# AM13E23219 register map
Vendor: Texas Instruments; File version: 1.0
CPU: CM33 r0p1, little endian, MPU, FPU, VTOR, 4 interrupt priority bits
Registers are 32-bit, read-write, reset 0x0 unless marked. A register's access mark holds for its fields unless they carry their own. Offsets are from the block's base; [hi:lo] are bit positions; lines under a group give offsets from that group; {n}, {i} and the like mark numbered series; 'fields as' and 'values as' point back to an identical list.

## INPUTXBAR — INPUT_XBAR module
Base 0x40468000
{0x0+4i} INPUTSELECT[{i}] (i=0..27) — Input Select Register (GPIO0 to x)
  [7:0] SELECT — Select GPIO for INPUT{#} signal
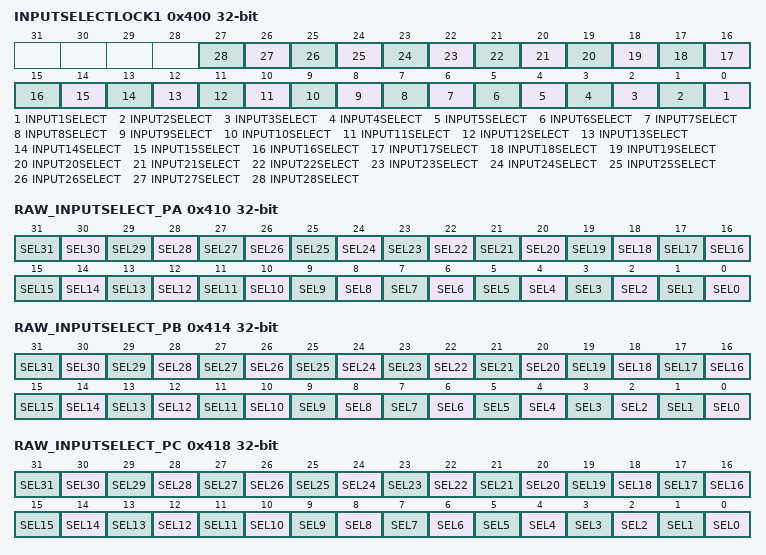
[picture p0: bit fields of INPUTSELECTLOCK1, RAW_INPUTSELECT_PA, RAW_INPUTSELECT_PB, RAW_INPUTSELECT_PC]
0x400 INPUTSELECTLOCK1 — Input Select Lock Register 1
  [n-1] INPUT{n}SELECT (n=1..28) — Lock bit for INPUT{n}SELECT Register
0x404 PINCM group
  {0x0+4j} I_GPIO0_SRC_IN_{j} (j=0..31) — GPIO0 pin {j} functional input signal from external pad to crossbar peripheral
    [30] GFLT — Glitch Filter Enable
      0=DISABLE (No internal glitch filter); 1=ENABLE (Use internal glitch filter)
    [29] SLEW — Reserved Slew Rate Control
      0=DISABLE (No Slew Rate Control); 1=ENABLE (Use Slew Rate Control)
    [28] WCOMP — Wake up compare value
      0=MATCH_ZERO (Match 0 will wake); 1=MATCH_ONE (Match 1 will wake)
    [27] WUEN — Wake up enable
      0=NO_WAKEUP (Wake up not enabled); 1=WAKEUP (Wake up enabled)
    [26] INV — Invert digital input/output relative to peripheral/GPIO
      0=NO_CHNG (Input and output are non-inverted); 1=CHNG (Input and output are inverted)
    [25] HIGHZ1 — High-Z instead of high output
      0=DRV_HIGH (Pin can be driven high); 1=DRV_HIZ (Pin is tri-stated instead of driven high)
    [24] HIGHZ0 — High-Z instead of low output
      0=DRV_LOW (Pin can be driven low); 1=DRV_HIZ (Pin is tri-stated instead of driven low)
    [22:20] DRV — Drive strength options
      0=STRENGTH_0 (Lowest drive strength); {v}=STRENGTH_{v} (Drive strength {v+1}/8) (v=1..6); 7=STRENGTH_7 (Highest drive strength)
    [19] HYSTEN — Hysteresis enable
      0=DIS_HYST (No hysteresis); 1=EN_HYST (Hysteresis on)
    [18] INENA — Input enable
      0=INP_DISABLE (Inputs 0 to connected core); 1=INP_ENABLE (Inputs IO pad value to connected core)
    [17] PIPU — Pull up enable
      0=NO_PULL_UP; 1=PULL_UP
    [16] PIPD — Pull down enable
      0=NO_PULL_DOWN; 1=PULL_DOWN
    [15:14] GSTATE — GPIO Channel State
      0=UNASSIGNED (G-Channel is in Unassigned State); 1=HANDOVER (G-Channel is in Handover State); 2=CONC_NOT_LOCKED (G-Channel is in Connected State and not Locked (That is F field is allowed to change without going back through Unassigned state)); 3=CONC_LOCKED (G-Channel is in Connected State and Locked (That is F field is not allowed to change to a different non-Zero value until both G and P channels go to Unassigned))
    [7:6] PSTATE — Peripheral-Analog Channel State
      0=UNASSIGNED (P-Channel is in Unassigned State); 1=HANDOVER (P-Channel is in Handover State); 2=CONC_NOT_LOCKED (P-Channel is in Connected State and not Locked (That is F field is allowed to change without going back through Unassigned state)); 3=CONC_LOCKED (P-Channel is in Connected State and Locked (That is F field is not allowed to change to a different non-Zero value until both G and P channels go to Unassigned))
  {0x80+4j} I_GPIO1_SRC_IN_{j} (j=0..31) — GPIO1 pin {j} functional input signal from external pad to crossbar peripheral
    fields as PINCM.I_GPIO0_SRC_IN_0
  {0x100+4j} I_GPIO2_SRC_IN_{j} (j=0..31) — GPIO2 pin {j} functional input signal from external pad to crossbar peripheral
    fields as PINCM.I_GPIO0_SRC_IN_0
  {0x180+4j} I_GPIO3_SRC_IN_{j} (j=0..31) — GPIO3 pin {j} functional input signal from external pad to crossbar peripheral
    fields as PINCM.I_GPIO0_SRC_IN_0
  {0x200+4j} I_GPIO0_SRC_ASYNC_IN_{j} (j=0..31) — GPIO0 pin {j} asynchronous functional input signal from external pad to crossbar peripheral
    fields as PINCM.I_GPIO0_SRC_IN_0
  {0x280+4j} I_GPIO1_SRC_ASYNC_IN_{j} (j=0..31) — GPIO1 pin {j} asynchronous functional input signal from external pad to crossbar peripheral
    fields as PINCM.I_GPIO0_SRC_IN_0
  {0x300+4j} I_GPIO2_SRC_ASYNC_IN_{j} (j=0..31) — GPIO2 pin {j} asynchronous functional input signal from external pad to crossbar peripheral
    fields as PINCM.I_GPIO0_SRC_IN_0
  {0x380+4j} I_GPIO3_SRC_ASYNC_IN_{j} (j=0..31) — GPIO3 pin {j} asynchronous functional input signal from external pad to crossbar peripheral
    fields as PINCM.I_GPIO0_SRC_IN_0
  {0x400+4j} O_OUTPUT_XBAR_OUTPUT{j} (j=0..11) — Single-bit crossbar output signal {j}
    fields as PINCM.I_GPIO0_SRC_IN_0
0x410 RAW_INPUTSELECT_PA — Raw Input Select Register for Port-A GPIOs
  [n] SEL{n} (n=0..31) — Raw input select bit for PA{n}
0x414 RAW_INPUTSELECT_PB — Raw Input Select Register for Port-B GPIOs
  [n] SEL{n} (n=0..31) — Raw input select bit for PB{n}
0x418 RAW_INPUTSELECT_PC — Raw Input Select Register for Port-C GPIOs
  [n] SEL{n} (n=0..31) — Raw input select bit for PC{n}
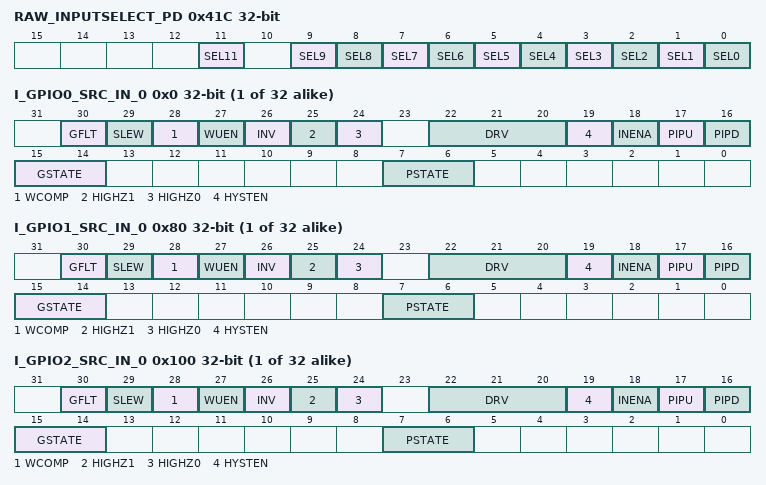
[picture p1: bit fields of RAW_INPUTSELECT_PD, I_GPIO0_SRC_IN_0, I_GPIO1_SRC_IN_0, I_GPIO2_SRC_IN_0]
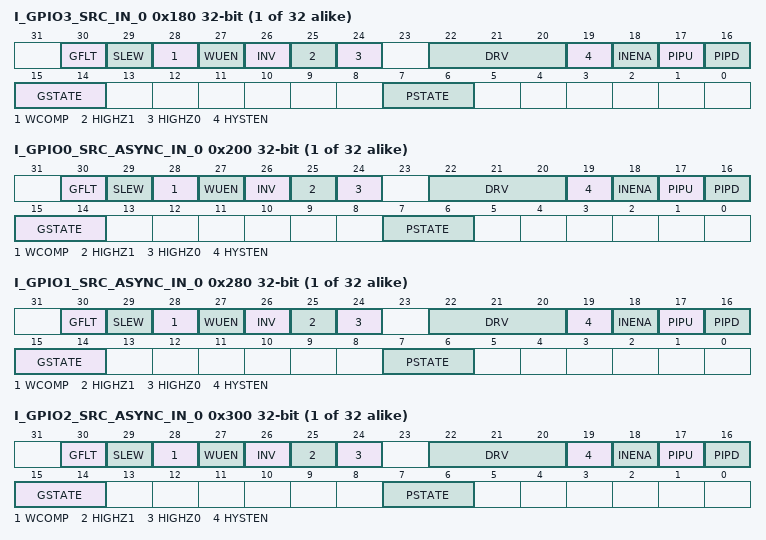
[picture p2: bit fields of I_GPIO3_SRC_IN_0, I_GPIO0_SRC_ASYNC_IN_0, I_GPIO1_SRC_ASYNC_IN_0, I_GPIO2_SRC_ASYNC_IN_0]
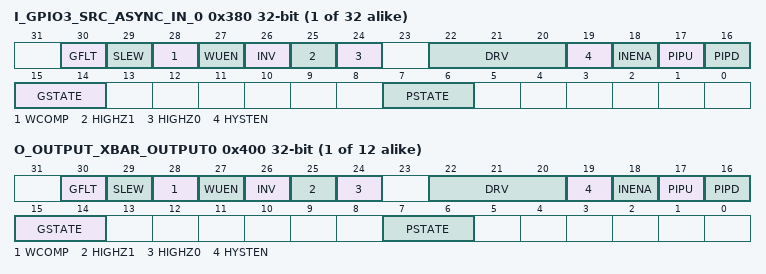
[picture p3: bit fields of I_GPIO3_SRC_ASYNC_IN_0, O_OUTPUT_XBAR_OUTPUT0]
0x41C RAW_INPUTSELECT_PD — Raw Input Select Register for Port-D GPIOs
  [11] SEL11 — Raw input select bit for PD11
  [n] SEL{n} (n=0..9) — Raw input select bit for PD{n}
0x604 FUPDATE group
  {0x0+4j} I_GPIO0_SRC_IN_{j} (j=0..31) — FUPDATE version of I_GPIO0_SRC_IN_{j}
    [27:2] IOADDR — IO Address. This is the address that corresponds to the SOC address[27:2] of the module IP instance specific IO signal in the "Full Write" subregion of the pinmux subregion.
    [1] LOCK — Sets lock bit
      0=NOEFFECT (Writing this value has no effect); 1=LOCK (Set channel lock bit)
    [0] GSEL — GPIO channel Select 0: Select the P-Channel for the F update 1: Select the G-Channel for the F update
      0=PCHAN (Select the P-Channel for the F update); 1=GCHAN (Select the G-Channel for the F update)
  {0x80+4j} I_GPIO1_SRC_IN_{j} (j=0..31) — FUPDATE version of I_GPIO1_SRC_IN_{j}
    fields as FUPDATE.I_GPIO0_SRC_IN_0
  {0x100+4j} I_GPIO2_SRC_IN_{j} (j=0..31) — FUPDATE version of I_GPIO2_SRC_IN_{j}
    fields as FUPDATE.I_GPIO0_SRC_IN_0
  {0x180+4j} I_GPIO3_SRC_IN_{j} (j=0..31) — FUPDATE version of I_GPIO3_SRC_IN_{j}
    fields as FUPDATE.I_GPIO0_SRC_IN_0
  {0x200+4j} I_GPIO0_SRC_ASYNC_IN_{j} (j=0..31) — FUPDATE version of I_GPIO0_SRC_ASYNC_IN_{j}
    fields as FUPDATE.I_GPIO0_SRC_IN_0
  {0x280+4j} I_GPIO1_SRC_ASYNC_IN_{j} (j=0..31) — FUPDATE version of I_GPIO1_SRC_ASYNC_IN_{j}
    fields as FUPDATE.I_GPIO0_SRC_IN_0
  {0x300+4j} I_GPIO2_SRC_ASYNC_IN_{j} (j=0..31) — FUPDATE version of I_GPIO2_SRC_ASYNC_IN_{j}
    fields as FUPDATE.I_GPIO0_SRC_IN_0
  {0x380+4j} I_GPIO3_SRC_ASYNC_IN_{j} (j=0..31) — FUPDATE version of I_GPIO3_SRC_ASYNC_IN_{j}
    fields as FUPDATE.I_GPIO0_SRC_IN_0
  {0x400+4j} O_OUTPUT_XBAR_OUTPUT{j} (j=0..11) — FUPDATE version of O_OUTPUT_XBAR_OUTPUT{j}
    fields as FUPDATE.I_GPIO0_SRC_IN_0
